# Special_Function_5 register map
Vendor: Texas Instruments
Peripheral module from a debugger description file (folder msp430).
Registers are 8-bit, read-write, reset 0x0 unless marked. A register's access mark holds for its fields unless they carry their own. Offsets are as the file gives them; lines under a group give offsets from that group; [hi:lo] are bit positions; {n}, {i} and the like mark numbered series; 'fields as' and 'values as' point back to an identical list; <NAME> marks a mode.

## Special_Function
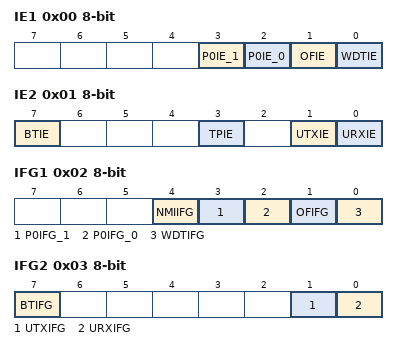
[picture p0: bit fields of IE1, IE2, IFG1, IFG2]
0x00 IE1 — Interrupt Enable 1
  [3] P0IE_1, [2] P0IE_0, [1] OFIE, [0] WDTIE
0x01 IE2 — Interrupt Enable 2
  [7] BTIE, [3] TPIE, [1] UTXIE, [0] URXIE
0x02 IFG1 — Interrupt Flag 1
  [4] NMIIFG, [3] P0IFG_1, [2] P0IFG_0, [1] OFIFG, [0] WDTIFG
0x03 IFG2 — Interrupt Flag 2
  [7] BTIFG, [1] UTXIFG, [0] URXIFG
0x05 ME2 — Module Enable 2
  [1] UTXE, [0] URXE, [0] USPIE
